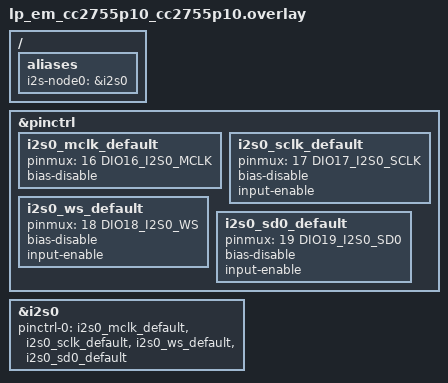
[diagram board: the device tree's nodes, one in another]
/* I2S API test overlay for lp_em_cc2755p10 */

/ {
	aliases {
		i2s-node0 = &i2s0;
	};
};

&pinctrl {
	i2s0_mclk_default: i2s0_mclk_default {
		pinmux = <16 DIO16_I2S0_MCLK>;
		bias-disable;
	};

	i2s0_sclk_default: i2s0_sclk_default {
		pinmux = <17 DIO17_I2S0_SCLK>;
		bias-disable;
		input-enable;
	};

	i2s0_ws_default: i2s0_ws_default {
		pinmux = <18 DIO18_I2S0_WS>;
		bias-disable;
		input-enable;
	};

	i2s0_sd0_default: i2s0_sd0_default {
		pinmux = <19 DIO19_I2S0_SD0>;
		bias-disable;
		input-enable;
	};
};

&i2s0 {
	status = "okay";
	pinctrl-0 = <&i2s0_mclk_default &i2s0_sclk_default
		     &i2s0_ws_default &i2s0_sd0_default>;
	pinctrl-names = "default";
};
